# MC1322x register map
Registers are 32-bit, access not given, no defined reset value unless marked. A register's access mark holds for its fields unless they carry their own. Addresses are absolute; registers are grouped by the start of their names; [hi:lo] are bit positions.

## UART1
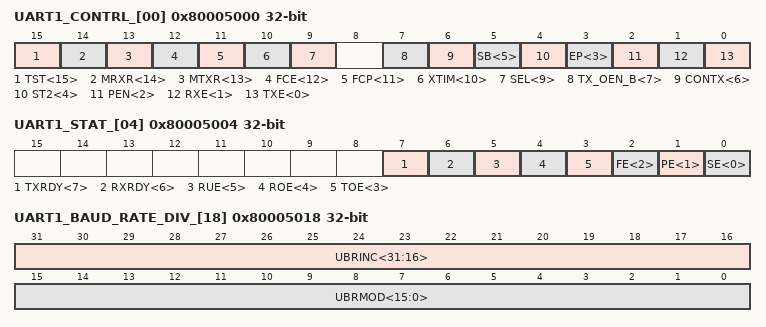
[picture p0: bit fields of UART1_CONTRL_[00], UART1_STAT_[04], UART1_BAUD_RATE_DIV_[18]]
0x80005000 UART1_CONTRL_[00]
  [15] TST<15>, [14] MRXR<14>, [13] MTXR<13>, [12] FCE<12>, [11] FCP<11>, [10] XTIM<10>, [9] SEL<9>, [7] TX_OEN_B<7>, [6] CONTX<6>, [5] SB<5>, [4] ST2<4>, [3] EP<3>, [2] PEN<2>, [1] RXE<1>, [0] TXE<0>
0x80005004 UART1_STAT_[04]
  [7] TXRDY<7>, [6] RXRDY<6>, [5] RUE<5>, [4] ROE<4>, [3] TOE<3>, [2] FE<2>, [1] PE<1>, [0] SE<0>
0x80005008 UART1_TRX_DATA_[08]_<7:0>
0x8000500C UART1_RXLEVEL_[0C]_<5:0>
0x80005010 UART1_TXLEVEL_[10]_<5:0>
0x80005014 UART1_CTS_LEVEL_[14]_<4:0>
0x80005018 UART1_BAUD_RATE_DIV_[18]
  [31:16] UBRINC<31:16>, [15:0] UBRMOD<15:0>

## I2C
0x80006000 I2C_ADDRESS_[00]_<7:1>
0x80006004 I2C_FREQ_DIV_[04]_<5:0>
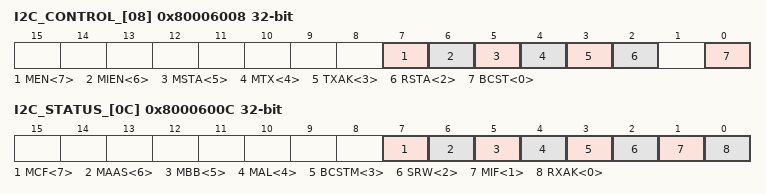
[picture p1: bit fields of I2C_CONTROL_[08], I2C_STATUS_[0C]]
0x80006008 I2C_CONTROL_[08]
  [7] MEN<7>, [6] MIEN<6>, [5] MSTA<5>, [4] MTX<4>, [3] TXAK<3>, [2] RSTA<2>, [0] BCST<0>
0x8000600C I2C_STATUS_[0C]
  [7] MCF<7>, [6] MAAS<6>, [5] MBB<5>, [4] MAL<4>, [3] BCSTM<3>, [2] SRW<2>, [1] MIF<1>, [0] RXAK<0>
0x80006010 I2C_DATA_[10]_<7:0>
0x80006014 I2C_DIG_FILTER_SMPL_RATE_[14]_<5:0>
0x80006018 I2C_CLOCK_EN_[18]_<0>

## TMR0
0x80007000 TMR0_COMPARISON_VALUE_1_[00]_<15:0> 16-bit
0x80007002 TMR0_COMPARISON_VALUE_2_[02]_<15:0> 16-bit
0x80007004 TMR0_CAPTURE_VALUE_[04]_<15:0> 16-bit
0x80007006 TMR0_LOAD_VALUE_[06]_<15:0> 16-bit
0x80007008 TMR0_HOLD_VALUE_[08]_<15:0> 16-bit
0x8000700A TMR0_COUNTER_[0A]_<15:0> 16-bit
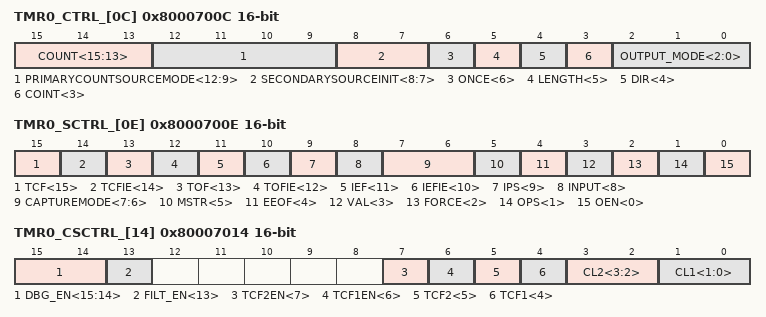
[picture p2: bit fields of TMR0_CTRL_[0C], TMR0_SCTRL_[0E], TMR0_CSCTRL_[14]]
0x8000700C TMR0_CTRL_[0C] 16-bit
  [15:13] COUNT<15:13>, [12:9] PRIMARYCOUNTSOURCEMODE<12:9>, [8:7] SECONDARYSOURCEINIT<8:7>, [6] ONCE<6>, [5] LENGTH<5>, [4] DIR<4>, [3] COINT<3>, [2:0] OUTPUT_MODE<2:0>
0x8000700E TMR0_SCTRL_[0E] 16-bit
  [15] TCF<15>, [14] TCFIE<14>, [13] TOF<13>, [12] TOFIE<12>, [11] IEF<11>, [10] IEFIE<10>, [9] IPS<9>, [8] INPUT<8>, [7:6] CAPTUREMODE<7:6>, [5] MSTR<5>, [4] EEOF<4>, [3] VAL<3>, [2] FORCE<2>, [1] OPS<1>, [0] OEN<0>
0x80007010 TMR0_COMPARATOR_LOAD_1_[10]_<15:0> 16-bit
0x80007012 TMR0_COMPARATOR_LOAD_2_[12]_<15:0> 16-bit
0x80007014 TMR0_CSCTRL_[14] 16-bit
  [15:14] DBG_EN<15:14>, [13] FILT_EN<13>, [7] TCF2EN<7>, [6] TCF1EN<6>, [5] TCF2<5>, [4] TCF1<4>, [3:2] CL2<3:2>, [1:0] CL1<1:0>

## TMR1
0x80007020 TMR1_COMPARISON_VALUE_1_[20]_<15:0> 16-bit
0x80007022 TMR1_COMPARISON_VALUE_2_[22]_<15:0> 16-bit
0x80007024 TMR1_CAPTURE_VALUE_[24]_<15:0> 16-bit
0x80007026 TMR1_LOAD_VALUE_[26]_<15:0> 16-bit
0x80007028 TMR1_HOLD_VALUE_[28]_<15:0> 16-bit
0x8000702A TMR1_COUNTER_[2A]_<15:0> 16-bit
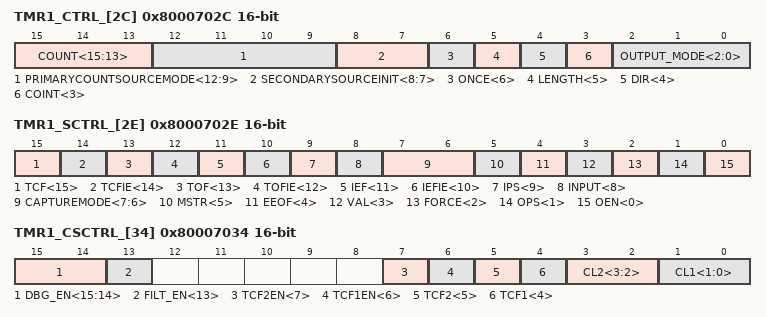
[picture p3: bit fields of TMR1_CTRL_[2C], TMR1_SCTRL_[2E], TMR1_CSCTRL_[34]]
0x8000702C TMR1_CTRL_[2C] 16-bit
  [15:13] COUNT<15:13>, [12:9] PRIMARYCOUNTSOURCEMODE<12:9>, [8:7] SECONDARYSOURCEINIT<8:7>, [6] ONCE<6>, [5] LENGTH<5>, [4] DIR<4>, [3] COINT<3>, [2:0] OUTPUT_MODE<2:0>
0x8000702E TMR1_SCTRL_[2E] 16-bit
  [15] TCF<15>, [14] TCFIE<14>, [13] TOF<13>, [12] TOFIE<12>, [11] IEF<11>, [10] IEFIE<10>, [9] IPS<9>, [8] INPUT<8>, [7:6] CAPTUREMODE<7:6>, [5] MSTR<5>, [4] EEOF<4>, [3] VAL<3>, [2] FORCE<2>, [1] OPS<1>, [0] OEN<0>
0x80007030 TMR1_COMPARATOR_LOAD_1_[30]_<15:0> 16-bit
0x80007032 TMR1_COMPARATOR_LOAD_2_[32]_<15:0> 16-bit
0x80007034 TMR1_CSCTRL_[34] 16-bit
  [15:14] DBG_EN<15:14>, [13] FILT_EN<13>, [7] TCF2EN<7>, [6] TCF1EN<6>, [5] TCF2<5>, [4] TCF1<4>, [3:2] CL2<3:2>, [1:0] CL1<1:0>

## TMR2
0x80007040 TMR2_COMPARISON_VALUE_1_[40]_<15:0> 16-bit
0x80007042 TMR2_COMPARISON_VALUE_2_[42]_<15:0> 16-bit
0x80007044 TMR2_CAPTURE_VALUE_[44]_<15:0> 16-bit
0x80007046 TMR2_LOAD_VALUE_[46]_<15:0> 16-bit
0x80007048 TMR2_HOLD_VALUE_[48]_<15:0> 16-bit
0x8000704A TMR2_COUNTER_[4A]_<15:0> 16-bit
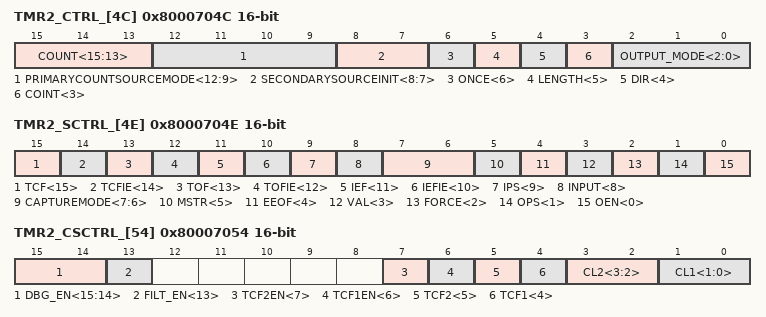
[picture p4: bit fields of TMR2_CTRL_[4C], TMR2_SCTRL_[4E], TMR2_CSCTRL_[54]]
0x8000704C TMR2_CTRL_[4C] 16-bit
  [15:13] COUNT<15:13>, [12:9] PRIMARYCOUNTSOURCEMODE<12:9>, [8:7] SECONDARYSOURCEINIT<8:7>, [6] ONCE<6>, [5] LENGTH<5>, [4] DIR<4>, [3] COINT<3>, [2:0] OUTPUT_MODE<2:0>
0x8000704E TMR2_SCTRL_[4E] 16-bit
  [15] TCF<15>, [14] TCFIE<14>, [13] TOF<13>, [12] TOFIE<12>, [11] IEF<11>, [10] IEFIE<10>, [9] IPS<9>, [8] INPUT<8>, [7:6] CAPTUREMODE<7:6>, [5] MSTR<5>, [4] EEOF<4>, [3] VAL<3>, [2] FORCE<2>, [1] OPS<1>, [0] OEN<0>
0x80007050 TMR2_COMPARATOR_LOAD_1_[50]_<15:0> 16-bit
0x80007052 TMR2_COMPARATOR_LOAD_2_[52]_<15:0> 16-bit
0x80007054 TMR2_CSCTRL_[54] 16-bit
  [15:14] DBG_EN<15:14>, [13] FILT_EN<13>, [7] TCF2EN<7>, [6] TCF1EN<6>, [5] TCF2<5>, [4] TCF1<4>, [3:2] CL2<3:2>, [1:0] CL1<1:0>
